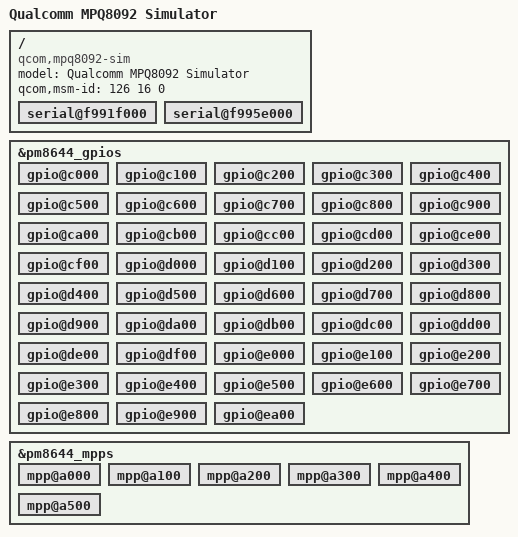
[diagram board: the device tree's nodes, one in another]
/* Copyright (c) 2012, The Linux Foundation. All rights reserved.
 *
 * This program is free software; you can redistribute it and/or modify
 * it under the terms of the GNU General Public License version 2 and
 * only version 2 as published by the Free Software Foundation.
 *
 * This program is distributed in the hope that it will be useful,
 * but WITHOUT ANY WARRANTY; without even the implied warranty of
 * MERCHANTABILITY or FITNESS FOR A PARTICULAR PURPOSE.  See the
 * GNU General Public License for more details.
 */

/dts-v1/;

/include/ "mpq8092.dtsi"

/ {
	model = "Qualcomm MPQ8092 Simulator";
	compatible = "qcom,mpq8092-sim", "qcom,mpq8092";
	qcom,msm-id = <126 16 0>;

	serial@f991f000 {
		status = "ok";
	};

	serial@f995e000 {
		status = "ok";
	};
};

&pm8644_gpios {
	gpio@c000 { /* GPIO 1 */
	};

	gpio@c100 { /* GPIO 2 */
	};

	gpio@c200 { /* GPIO 3 */
	};

	gpio@c300 { /* GPIO 4 */
	};

	gpio@c400 { /* GPIO 5 */
	};

	gpio@c500 { /* GPIO 6 */
	};

	gpio@c600 { /* GPIO 7 */
	};

	gpio@c700 { /* GPIO 8 */
	};

	gpio@c800 { /* GPIO 9 */
	};

	gpio@c900 { /* GPIO 10 */
	};

	gpio@ca00 { /* GPIO 11 */
	};

	gpio@cb00 { /* GPIO 12 */
	};

	gpio@cc00 { /* GPIO 13 */
	};

	gpio@cd00 { /* GPIO 14 */
	};

	gpio@ce00 { /* GPIO 15 */
	};

	gpio@cf00 { /* GPIO 16 */
	};

	gpio@d000 { /* GPIO 17 */
	};

	gpio@d100 { /* GPIO 18 */
	};

	gpio@d200 { /* GPIO 19 */
	};

	gpio@d300 { /* GPIO 20 */
	};

	gpio@d400 { /* GPIO 21 */
	};

	gpio@d500 { /* GPIO 22 */
	};

	gpio@d600 { /* GPIO 23 */
	};

	gpio@d700 { /* GPIO 24 */
	};

	gpio@d800 { /* GPIO 25 */
	};

	gpio@d900 { /* GPIO 26 */
	};

	gpio@da00 { /* GPIO 27 */
	};

	gpio@db00 { /* GPIO 28 */
	};

	gpio@dc00 { /* GPIO 29 */
	};

	gpio@dd00 { /* GPIO 30 */
	};

	gpio@de00 { /* GPIO 31 */
	};

	gpio@df00 { /* GPIO 32 */
	};

	gpio@e000 { /* GPIO 33 */
	};

	gpio@e100 { /* GPIO 34 */
	};

	gpio@e200 { /* GPIO 35 */
	};

	gpio@e300 { /* GPIO 36 */
	};

	gpio@e400 { /* GPIO 37 */
	};

	gpio@e500 { /* GPIO 38 */
	};

	gpio@e600 { /* GPIO 39 */
	};

	gpio@e700 { /* GPIO 40 */
	};

	gpio@e800 { /* GPIO 41 */
	};

	gpio@e900 { /* GPIO 42 */
	};

	gpio@ea00 { /* GPIO 43 */
	};
};

&pm8644_mpps {
	mpp@a000 { /* MPP 1 */
	};

	mpp@a100 { /* MPP 2 */
	};

	mpp@a200 { /* MPP 3 */
	};

	mpp@a300 { /* MPP 4 */
	};

	mpp@a400 { /* MPP5 */
	};

	mpp@a500 { /* MPP 6 */
	};
};
